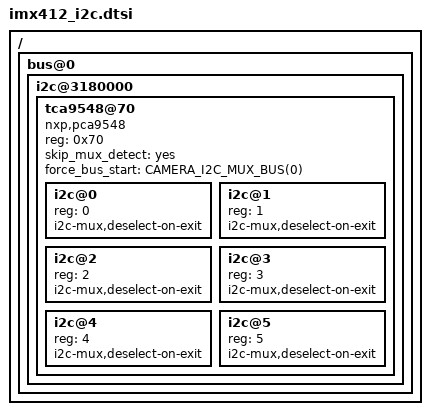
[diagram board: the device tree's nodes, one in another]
/*
 * Copyright (C) 2022, Leopardimaging Inc.
 * Based on Copyright (c) 2017-2022, NVIDIA CORPORATION.  All rights reserved.
 *
 * This program is free software; you can redistribute it and/or modify it
 * under the terms and conditions of the GNU General Public License,
 * version 2, as published by the Free Software Foundation.
 *
 * This program is distributed in the hope it will be useful, but WITHOUT
 * ANY WARRANTY; without even the implied warranty of MERCHANTABILITY or
 * FITNESS FOR A PARTICULAR PURPOSE.  See the GNU General Public License for
 * more details.
 *
 * You should have received a copy of the GNU General Public License
 * along with this program.  If not, see <http://www.gnu.org/licenses/>.
 */
//  #include <t234-common-modules/tegra234-camera-imx477-a00.dtsi>
#include <overlay/tegra234-p3737-camera-imx477.dtsi>
 #include "dt-bindings/clock/tegra234-clock.h"
 
 /*
 #define CAM0_RST_L	TEGRA234_MAIN_GPIO(H, 3)
 #define CAM0_PWDN	TEGRA234_MAIN_GPIO(H, 6)
 #define CAM1_RST_L	TEGRA234_MAIN_GPIO(AC, 2)
 #define CAM1_PWDN	TEGRA234_MAIN_GPIO(AC, 0)
 #define CAM4_PWDN	TEGRA234_MAIN_GPIO(H, 4)
 #define CAM5_PWDN	TEGRA234_MAIN_GPIO(AC, 1)
 */
 #define CAMERA_I2C_MUX_BUS(x) (0x1E + x)
 
 /* camera control gpio definitions */
 
 / {
     /*gpio@2200000 {
         camera-control-output-low {
             gpio-hog;
             output-low;
             gpios = <CAM0_RST_L 0>;
             label = "cam0-rst";
         };
     };*/

    //  aliases {
    //     i2c30 = &i2c_mux_bus_30;
    //     i2c31 = &i2c_mux_bus_31;
    //     i2c32 = &i2c_mux_bus_32;
    //     i2c33 = &i2c_mux_bus_33;
    //     i2c34 = &i2c_mux_bus_34;
    //     i2c35 = &i2c_mux_bus_35;
    // };

     bus@0{
 
        i2c@3180000 {
            tca9548@70 {
                status = "okay";
                compatible = "nxp,pca9548";
                reg = <0x70>;
                #address-cells = <1>;
                #size-cells = <0>;
                skip_mux_detect = "yes";
                //  vcc-supply = <&p3737_vdd_1v8_sys>;
                //  vcc-pullup-supply = <&battery_reg>;
                force_bus_start = <CAMERA_I2C_MUX_BUS(0)>;
    
                i2c@0 {
                    reg = <0>;
                    i2c-mux,deselect-on-exit;
                    #address-cells = <1>;
                    #size-cells = <0>;
                    /*imx477_a@1a {
                        reset-gpios = <&tegra_main_gpio CAM0_RST_L GPIO_ACTIVE_HIGH>;
                    };*/
                };
                i2c@1 {
                    reg = <1>;
                    i2c-mux,deselect-on-exit;
                    #address-cells = <1>;
                    #size-cells = <0>;
                    /*imx477_b@1a {
                        reset-gpios = <&tegra_main_gpio CAM0_PWDN GPIO_ACTIVE_HIGH>;
                    };*/
                };
                i2c@2 {
                    reg = <2>;
                    i2c-mux,deselect-on-exit;
                    #address-cells = <1>;
                    #size-cells = <0>;
                    /*imx477_c@1a {
                        reset-gpios = <&tegra_main_gpio CAM1_RST_L GPIO_ACTIVE_HIGH>;
                    };*/
                };
                i2c@3 {
                    reg = <3>;
                    i2c-mux,deselect-on-exit;
                    #address-cells = <1>;
                    #size-cells = <0>;
    
                    /*imx477_d@1a {
                        reset-gpios = <&tegra_main_gpio CAM1_PWDN GPIO_ACTIVE_HIGH>;
                    };*/
                };
                i2c@4 {
                    reg = <4>;
                    i2c-mux,deselect-on-exit;
                    #address-cells = <1>;
                    #size-cells = <0>;
    
                    /*imx477_e@1a {
                        reset-gpios = <&tegra_main_gpio CAM4_PWDN GPIO_ACTIVE_HIGH>;
                    };*/
                };
                i2c@5 {
                    reg = <5>;
                    i2c-mux,deselect-on-exit;
                    #address-cells = <1>;
                    #size-cells = <0>;
    
                    /*imx477_g@1a {
                        reset-gpios = <&tegra_main_gpio CAM5_PWDN GPIO_ACTIVE_HIGH>;
                    };*/
                };
            };
        };
    };
 };
 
